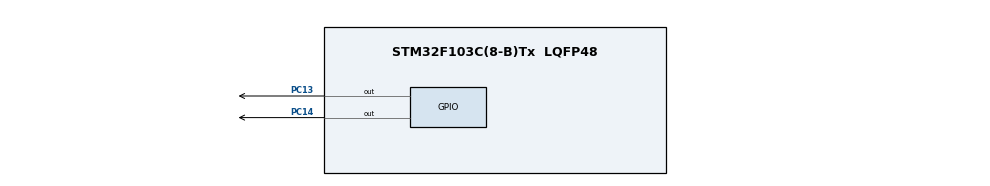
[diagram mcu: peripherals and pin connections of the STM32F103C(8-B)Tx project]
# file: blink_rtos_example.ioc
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FREERTOS.Tasks01=defaultTask,0,128,StartDefaultTask,Default,NULL
Mcu.Family=STM32F1
Mcu.Name=STM32F103C(8-B)Tx
Mcu.Package=LQFP48
NVIC.PriorityGroup=NVIC_PRIORITYGROUP_4
PA13.Mode=Serial_Wire
PA13.Signal=SYS_JTMS-SWDIO
PA14.Mode=Serial_Wire
PA14.Signal=SYS_JTCK-SWCLK
PC13-TAMPER-RTC.Signal=GPIO_Output
PC14-OSC32_IN.Signal=GPIO_Output
ProjectManager.HeapSize=0x200
ProjectManager.StackSize=0x400
ProjectManager.TargetToolchain=STM32CubeIDE
RCC.APB1Freq_Value=8000000
RCC.APB2Freq_Value=8000000
VP_FREERTOS_VS_CMSIS_V1.Mode=CMSIS_V1
board=custom

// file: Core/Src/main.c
#include "main.h"
#include "cmsis_os.h"
#include "task.h"
#include "FreeRTOS.h"

osThreadId pc13TaskHandle;
osThreadId pc14TaskHandle;
void SystemClock_Config(void);
static void MX_GPIO_Init(void);
void led_pc13_task(void const * argument);
void led_pc14_task(void const * argument);
void *blink_function(void);

int main(void)
{

  HAL_Init();

  SystemClock_Config();

  MX_GPIO_Init();

  osThreadDef(pc13Task,led_pc13_task, osPriorityNormal, 0, 100);
  pc13TaskHandle = osThreadCreate(osThread(pc13Task), NULL);

  osThreadDef(pc14Task,led_pc14_task, osPriorityNormal, 0, 100);
  pc14TaskHandle = osThreadCreate(osThread(pc14Task), NULL);

  osKernelStart();

  while (1)
  {

  }

}

void SystemClock_Config(void)
{
  RCC_OscInitTypeDef RCC_OscInitStruct = {0};
  RCC_ClkInitTypeDef RCC_ClkInitStruct = {0};

  /** Initializes the CPU, AHB and APB busses clocks
  */
  RCC_OscInitStruct.OscillatorType = RCC_OSCILLATORTYPE_HSI;
  RCC_OscInitStruct.HSIState = RCC_HSI_ON;
  RCC_OscInitStruct.HSICalibrationValue = RCC_HSICALIBRATION_DEFAULT;
  RCC_OscInitStruct.PLL.PLLState = RCC_PLL_NONE;
  if (HAL_RCC_OscConfig(&RCC_OscInitStruct) != HAL_OK)
  {
    Error_Handler();
  }
  /** Initializes the CPU, AHB and APB busses clocks
  */
  RCC_ClkInitStruct.ClockType = RCC_CLOCKTYPE_HCLK|RCC_CLOCKTYPE_SYSCLK
                              |RCC_CLOCKTYPE_PCLK1|RCC_CLOCKTYPE_PCLK2;
  RCC_ClkInitStruct.SYSCLKSource = RCC_SYSCLKSOURCE_HSI;
  RCC_ClkInitStruct.AHBCLKDivider = RCC_SYSCLK_DIV1;
  RCC_ClkInitStruct.APB1CLKDivider = RCC_HCLK_DIV1;
  RCC_ClkInitStruct.APB2CLKDivider = RCC_HCLK_DIV1;

  if (HAL_RCC_ClockConfig(&RCC_ClkInitStruct, FLASH_LATENCY_0) != HAL_OK)
  {
    Error_Handler();
  }
}

static void MX_GPIO_Init(void)
{
  GPIO_InitTypeDef GPIO_InitStruct = {0};

  /* GPIO Ports Clock Enable */
  __HAL_RCC_GPIOC_CLK_ENABLE();
  __HAL_RCC_GPIOD_CLK_ENABLE();
  __HAL_RCC_GPIOA_CLK_ENABLE();
  __HAL_RCC_GPIOB_CLK_ENABLE();
  __HAL_RCC_GPIOE_CLK_ENABLE();

  /*Configure GPIO pin Output Level */
  HAL_GPIO_WritePin(GPIOC, GPIO_PIN_13|GPIO_PIN_14, GPIO_PIN_RESET);

  /*Configure GPIO pins : PC13 PC14 */
  GPIO_InitStruct.Pin = GPIO_PIN_13|GPIO_PIN_14;
  GPIO_InitStruct.Mode = GPIO_MODE_OUTPUT_PP;
  GPIO_InitStruct.Pull = GPIO_NOPULL;
  GPIO_InitStruct.Speed = GPIO_SPEED_FREQ_LOW;
  HAL_GPIO_Init(GPIOC, &GPIO_InitStruct);

  /*Configure GPIO pin : PC15 */
  GPIO_InitStruct.Pin = GPIO_PIN_15;
  GPIO_InitStruct.Mode = GPIO_MODE_ANALOG;
  HAL_GPIO_Init(GPIOC, &GPIO_InitStruct);

  /*Configure GPIO pins : PD0 PD1 */
  GPIO_InitStruct.Pin = GPIO_PIN_0|GPIO_PIN_1;
  GPIO_InitStruct.Mode = GPIO_MODE_ANALOG;
  HAL_GPIO_Init(GPIOD, &GPIO_InitStruct);

  /*Configure GPIO pins : PA0 PA1 PA2 PA3
                           PA4 PA5 PA6 PA7
                           PA8 PA9 PA10 PA11
                           PA12 PA15 */
  GPIO_InitStruct.Pin = GPIO_PIN_0|GPIO_PIN_1|GPIO_PIN_2|GPIO_PIN_3
                          |GPIO_PIN_4|GPIO_PIN_5|GPIO_PIN_6|GPIO_PIN_7
                          |GPIO_PIN_8|GPIO_PIN_9|GPIO_PIN_10|GPIO_PIN_11
                          |GPIO_PIN_12|GPIO_PIN_15;
  GPIO_InitStruct.Mode = GPIO_MODE_ANALOG;
  HAL_GPIO_Init(GPIOA, &GPIO_InitStruct);

  /*Configure GPIO pins : PB0 PB1 PB2 PB10
                           PB11 PB12 PB13 PB14
                           PB15 PB3 PB4 PB5
                           PB6 PB7 PB8 PB9 */
  GPIO_InitStruct.Pin = GPIO_PIN_0|GPIO_PIN_1|GPIO_PIN_2|GPIO_PIN_10
                          |GPIO_PIN_11|GPIO_PIN_12|GPIO_PIN_13|GPIO_PIN_14
                          |GPIO_PIN_15|GPIO_PIN_3|GPIO_PIN_4|GPIO_PIN_5
                          |GPIO_PIN_6|GPIO_PIN_7|GPIO_PIN_8|GPIO_PIN_9;
  GPIO_InitStruct.Mode = GPIO_MODE_ANALOG;
  HAL_GPIO_Init(GPIOB, &GPIO_InitStruct);

  /*Configure peripheral I/O remapping */
  __HAL_AFIO_REMAP_PD01_ENABLE();

}

void led_pc13_task(void const * argument)
{
  /* USER CODE BEGIN 5 */
  /* Infinite loop */
  for(;;)
  {
	  HAL_GPIO_TogglePin(GPIOC, GPIO_PIN_13);
	  		  		for(int x=0; x<80000;x+=2);

  }
  /* USER CODE END 5 */
}

void led_pc14_task(void const * argument)
{
  /* USER CODE BEGIN 5 */
  /* Infinite loop */
  for(;;)
  {
	  HAL_GPIO_TogglePin(GPIOC, GPIO_PIN_14);
	  		  		for(int x=0; x<80000;x++);

  }
  /* USER CODE END 5 */
}
void Error_Handler(void)
{
}

void *blink_function(void)
{
	 while (1)
	  {
		  HAL_GPIO_TogglePin(GPIOC, GPIO_PIN_13);
		  		for(int x=0; x<80000;x++);
	  }
}

/************************ (C) COPYRIGHT STMicroelectronics *****END OF FILE****/
